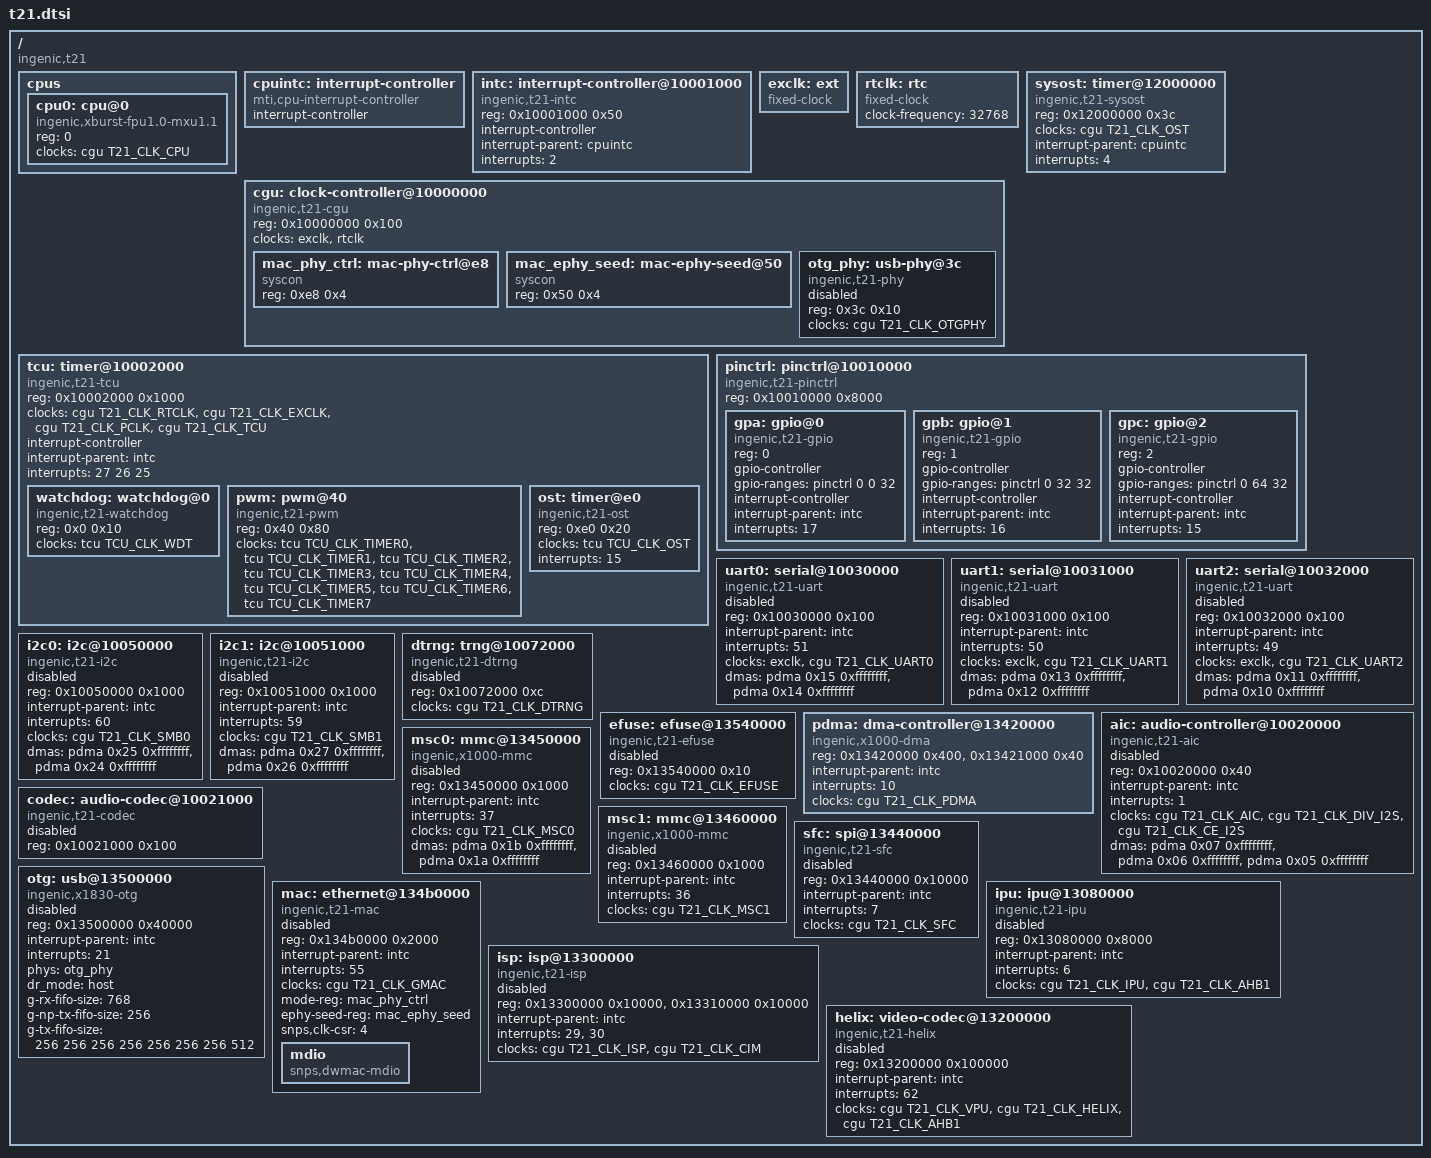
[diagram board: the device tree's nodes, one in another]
// SPDX-License-Identifier: GPL-2.0
#include <dt-bindings/clock/ingenic,tcu.h>
#include <dt-bindings/clock/ingenic,t21-cgu.h>

/ {
	#address-cells = <1>;
	#size-cells = <1>;
	compatible = "ingenic,t21";

	cpus {
		#address-cells = <1>;
		#size-cells = <0>;

		cpu0: cpu@0 {
			device_type = "cpu";
			compatible = "ingenic,xburst-fpu1.0-mxu1.1";
			reg = <0>;

			clocks = <&cgu T21_CLK_CPU>;
			clock-names = "cpu";
		};
	};

	cpuintc: interrupt-controller {
		#address-cells = <0>;
		#interrupt-cells = <1>;
		interrupt-controller;
		compatible = "mti,cpu-interrupt-controller";
	};

	intc: interrupt-controller@10001000 {
		compatible = "ingenic,t21-intc", "ingenic,jz4780-intc";
		reg = <0x10001000 0x50>;

		interrupt-controller;
		#interrupt-cells = <1>;

		interrupt-parent = <&cpuintc>;
		interrupts = <2>;
	};

	exclk: ext {
		compatible = "fixed-clock";
		#clock-cells = <0>;
	};

	rtclk: rtc {
		compatible = "fixed-clock";
		#clock-cells = <0>;
		clock-frequency = <32768>;
	};

	cgu: clock-controller@10000000 {
		compatible = "ingenic,t21-cgu", "simple-mfd";
		reg = <0x10000000 0x100>;
		#address-cells = <1>;
		#size-cells = <1>;
		ranges = <0x0 0x10000000 0x100>;

		#clock-cells = <1>;

		clocks = <&exclk>, <&rtclk>;
		clock-names = "ext", "rtc";

		mac_phy_ctrl: mac-phy-ctrl@e8 {
			compatible = "syscon";
			reg = <0xe8 0x4>;
		};

		mac_ephy_seed: mac-ephy-seed@50 {
			compatible = "syscon";
			reg = <0x50 0x4>;
		};

		otg_phy: usb-phy@3c {
			compatible = "ingenic,t21-phy";
			reg = <0x3c 0x10>;

			clocks = <&cgu T21_CLK_OTGPHY>;

			#phy-cells = <0>;

			status = "disabled";
		};
	};

	sysost: timer@12000000 {
		compatible = "ingenic,t21-sysost", "ingenic,x1000-ost";
		reg = <0x12000000 0x3c>;

		#clock-cells = <1>;

		clocks = <&cgu T21_CLK_OST>;
		clock-names = "ost";

		interrupt-parent = <&cpuintc>;
		interrupts = <4>;
	};

	tcu: timer@10002000 {
		compatible = "ingenic,t21-tcu", "ingenic,jz4760-tcu",
			     "simple-mfd";
		reg = <0x10002000 0x1000>;
		#address-cells = <1>;
		#size-cells = <1>;
		ranges = <0x0 0x10002000 0x1000>;

		#clock-cells = <1>;

		clocks = <&cgu T21_CLK_RTCLK>,
			 <&cgu T21_CLK_EXCLK>,
			 <&cgu T21_CLK_PCLK>,
			 <&cgu T21_CLK_TCU>;
		clock-names = "rtc", "ext", "pclk", "tcu";

		interrupt-controller;
		#interrupt-cells = <1>;

		interrupt-parent = <&intc>;
		interrupts = <27 26 25>;

		watchdog: watchdog@0 {
			compatible = "ingenic,t21-watchdog",
				     "ingenic,jz4780-watchdog";
			reg = <0x0 0x10>;

			clocks = <&tcu TCU_CLK_WDT>;
			clock-names = "wdt";
		};

		pwm: pwm@40 {
			compatible = "ingenic,t21-pwm", "ingenic,jz4740-pwm";
			reg = <0x40 0x80>;

			#pwm-cells = <3>;

			clocks = <&tcu TCU_CLK_TIMER0>,
				 <&tcu TCU_CLK_TIMER1>,
				 <&tcu TCU_CLK_TIMER2>,
				 <&tcu TCU_CLK_TIMER3>,
				 <&tcu TCU_CLK_TIMER4>,
				 <&tcu TCU_CLK_TIMER5>,
				 <&tcu TCU_CLK_TIMER6>,
				 <&tcu TCU_CLK_TIMER7>;
			clock-names = "timer0", "timer1", "timer2", "timer3",
				      "timer4", "timer5", "timer6", "timer7";
		};

		ost: timer@e0 {
			compatible = "ingenic,t21-ost", "ingenic,jz4760b-ost";
			reg = <0xe0 0x20>;

			clocks = <&tcu TCU_CLK_OST>;
			clock-names = "ost";

			interrupts = <15>;
		};
	};

	pinctrl: pinctrl@10010000 {
		compatible = "ingenic,t21-pinctrl";
		reg = <0x10010000 0x8000>;

		#address-cells = <1>;
		#size-cells = <0>;

		gpa: gpio@0 {
			compatible = "ingenic,t21-gpio";
			reg = <0>;

			gpio-controller;
			gpio-ranges = <&pinctrl 0 0 32>;
			#gpio-cells = <2>;

			interrupt-controller;
			#interrupt-cells = <2>;

			interrupt-parent = <&intc>;
			interrupts = <17>;
		};

		gpb: gpio@1 {
			compatible = "ingenic,t21-gpio";
			reg = <1>;

			gpio-controller;
			gpio-ranges = <&pinctrl 0 32 32>;
			#gpio-cells = <2>;

			interrupt-controller;
			#interrupt-cells = <2>;

			interrupt-parent = <&intc>;
			interrupts = <16>;
		};

		gpc: gpio@2 {
			compatible = "ingenic,t21-gpio";
			reg = <2>;

			gpio-controller;
			gpio-ranges = <&pinctrl 0 64 32>;
			#gpio-cells = <2>;

			interrupt-controller;
			#interrupt-cells = <2>;

			interrupt-parent = <&intc>;
			interrupts = <15>;
		};
	};

	uart0: serial@10030000 {
		compatible = "ingenic,t21-uart", "ingenic,x1000-uart";
		reg = <0x10030000 0x100>;

		interrupt-parent = <&intc>;
		interrupts = <51>;

		clocks = <&exclk>, <&cgu T21_CLK_UART0>;
		clock-names = "baud", "module";

		dmas = <&pdma 0x15 0xffffffff>, <&pdma 0x14 0xffffffff>;
		dma-names = "rx", "tx";

		status = "disabled";
	};

	uart1: serial@10031000 {
		compatible = "ingenic,t21-uart", "ingenic,x1000-uart";
		reg = <0x10031000 0x100>;

		interrupt-parent = <&intc>;
		interrupts = <50>;

		clocks = <&exclk>, <&cgu T21_CLK_UART1>;
		clock-names = "baud", "module";

		dmas = <&pdma 0x13 0xffffffff>, <&pdma 0x12 0xffffffff>;
		dma-names = "rx", "tx";

		status = "disabled";
	};

	uart2: serial@10032000 {
		compatible = "ingenic,t21-uart", "ingenic,x1000-uart";
		reg = <0x10032000 0x100>;

		interrupt-parent = <&intc>;
		interrupts = <49>;

		clocks = <&exclk>, <&cgu T21_CLK_UART2>;
		clock-names = "baud", "module";

		dmas = <&pdma 0x11 0xffffffff>, <&pdma 0x10 0xffffffff>;
		dma-names = "rx", "tx";

		status = "disabled";
	};

	i2c0: i2c@10050000 {
		compatible = "ingenic,t21-i2c", "ingenic,x1000-i2c";
		reg = <0x10050000 0x1000>;

		interrupt-parent = <&intc>;
		interrupts = <60>;

		clocks = <&cgu T21_CLK_SMB0>;

		dmas = <&pdma 0x25 0xffffffff>, <&pdma 0x24 0xffffffff>;
		dma-names = "rx", "tx";

		#address-cells = <1>;
		#size-cells = <0>;

		status = "disabled";
	};

	i2c1: i2c@10051000 {
		compatible = "ingenic,t21-i2c", "ingenic,x1000-i2c";
		reg = <0x10051000 0x1000>;

		interrupt-parent = <&intc>;
		interrupts = <59>;

		clocks = <&cgu T21_CLK_SMB1>;

		dmas = <&pdma 0x27 0xffffffff>, <&pdma 0x26 0xffffffff>;
		dma-names = "rx", "tx";

		#address-cells = <1>;
		#size-cells = <0>;

		status = "disabled";
	};

	dtrng: trng@10072000 {
		compatible = "ingenic,t21-dtrng", "ingenic,x1830-dtrng";
		reg = <0x10072000 0xc>;

		clocks = <&cgu T21_CLK_DTRNG>;

		status = "disabled";
	};

	efuse: efuse@13540000 {
		compatible = "ingenic,t21-efuse";
		reg = <0x13540000 0x10>;

		clocks = <&cgu T21_CLK_EFUSE>;

		status = "disabled";
	};

	pdma: dma-controller@13420000 {
		compatible = "ingenic,x1000-dma";
		reg = <0x13420000 0x400>, <0x13421000 0x40>;

		interrupt-parent = <&intc>;
		interrupts = <10>;

		clocks = <&cgu T21_CLK_PDMA>;

		#dma-cells = <2>;
	};

	aic: audio-controller@10020000 {
		compatible = "ingenic,t21-aic";
		reg = <0x10020000 0x40>;

		interrupt-parent = <&intc>;
		interrupts = <1>;

		clocks = <&cgu T21_CLK_AIC>,
			 <&cgu T21_CLK_DIV_I2S>,
			 <&cgu T21_CLK_CE_I2S>;
		clock-names = "gate_aic", "div_i2s", "ce_i2s";

		dmas = <&pdma 0x07 0xffffffff>,
		       <&pdma 0x06 0xffffffff>,
		       <&pdma 0x05 0xffffffff>;
		dma-names = "rx", "tx", "aec";

		status = "disabled";
	};

	codec: audio-codec@10021000 {
		compatible = "ingenic,t21-codec";
		reg = <0x10021000 0x100>;

		status = "disabled";
	};

	msc0: mmc@13450000 {
		compatible = "ingenic,x1000-mmc";
		reg = <0x13450000 0x1000>;

		interrupt-parent = <&intc>;
		interrupts = <37>;

		clocks = <&cgu T21_CLK_MSC0>;
		clock-names = "mmc";

		dmas = <&pdma 0x1b 0xffffffff>,
		       <&pdma 0x1a 0xffffffff>;
		dma-names = "rx", "tx";

		status = "disabled";
	};

	msc1: mmc@13460000 {
		compatible = "ingenic,x1000-mmc";
		reg = <0x13460000 0x1000>;

		interrupt-parent = <&intc>;
		interrupts = <36>;

		clocks = <&cgu T21_CLK_MSC1>;
		clock-names = "mmc";

		status = "disabled";
	};

	sfc: spi@13440000 {
		compatible = "ingenic,t21-sfc", "ingenic,x1000-sfc";
		reg = <0x13440000 0x10000>;

		interrupt-parent = <&intc>;
		interrupts = <7>;

		clocks = <&cgu T21_CLK_SFC>;
		clock-names = "sfc";

		#address-cells = <1>;
		#size-cells = <0>;

		status = "disabled";
	};

	otg: usb@13500000 {
		compatible = "ingenic,x1830-otg";
		reg = <0x13500000 0x40000>;

		interrupt-parent = <&intc>;
		interrupts = <21>;

		phys = <&otg_phy>;
		phy-names = "usb2-phy";

		dr_mode = "host";

		g-rx-fifo-size = <768>;
		g-np-tx-fifo-size = <256>;
		g-tx-fifo-size = <256 256 256 256 256 256 256 512>;

		status = "disabled";
	};

	mac: ethernet@134b0000 {
		compatible = "ingenic,t21-mac", "snps,dwmac";
		reg = <0x134b0000 0x2000>;

		interrupt-parent = <&intc>;
		interrupts = <55>;
		interrupt-names = "macirq";

		clocks = <&cgu T21_CLK_GMAC>;
		clock-names = "stmmaceth";

		mode-reg = <&mac_phy_ctrl>;
		ephy-seed-reg = <&mac_ephy_seed>;

		snps,clk-csr = <4>;

		status = "disabled";

		mdio: mdio {
			compatible = "snps,dwmac-mdio";
			#address-cells = <1>;
			#size-cells = <0>;
		};
	};

/*
	 * The IPU libimp draws its OSD with, through the out-of-tree ipu module
	 * (/dev/ipu). Disabled: the module makes its device from this node.
	 */
	ipu: ipu@13080000 {
		compatible = "ingenic,t21-ipu";
		reg = <0x13080000 0x8000>;

		interrupt-parent = <&intc>;
		interrupts = <6>;

		clocks = <&cgu T21_CLK_IPU>, <&cgu T21_CLK_AHB1>;
		clock-names = "ipu", "ahb1";

		status = "disabled";
	};

	isp: isp@13300000 {
		compatible = "ingenic,t21-isp";
		reg = <0x13300000 0x10000>, <0x13310000 0x10000>;
		reg-names = "isp", "vic";

		interrupt-parent = <&intc>;
		interrupts = <29>, <30>;
		interrupt-names = "isp", "vic";

		clocks = <&cgu T21_CLK_ISP>, <&cgu T21_CLK_CIM>;
		clock-names = "isp", "cim";

		status = "disabled";
	};

	helix: video-codec@13200000 {
		compatible = "ingenic,t21-helix";
		reg = <0x13200000 0x100000>;

		interrupt-parent = <&intc>;
		interrupts = <62>;

		clocks = <&cgu T21_CLK_VPU>, <&cgu T21_CLK_HELIX>, <&cgu T21_CLK_AHB1>;
		clock-names = "vpu", "helix", "ahb1";

		status = "disabled";
	};
};
